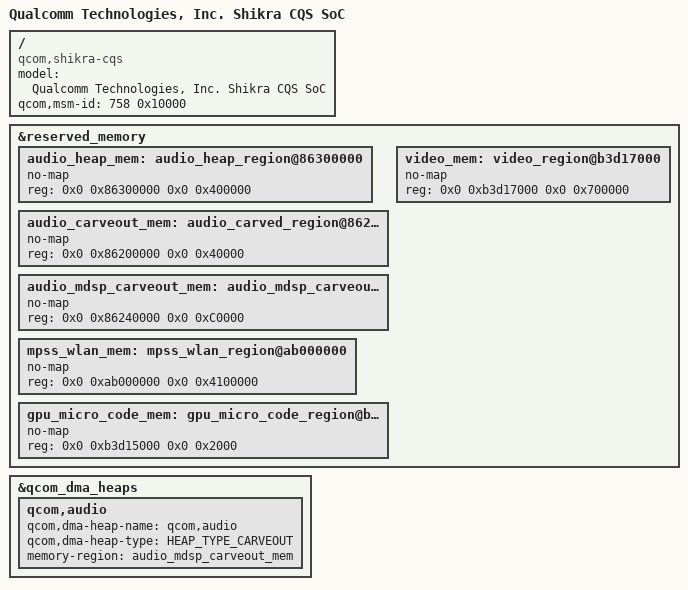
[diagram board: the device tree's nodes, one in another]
// SPDX-License-Identifier: BSD-3-Clause
/*
 * Copyright (c) Qualcomm Technologies, Inc. and/or its subsidiaries.
 */

#include "shikra.dtsi"
#include "shikra-pmic-overlay-pm4125.dtsi"

/ {
	model = "Qualcomm Technologies, Inc. Shikra CQS SoC";
	compatible = "qcom,shikra-cqs";
	qcom,msm-id = <758 0x10000>;
};

&reserved_memory {
	#address-cells = <2>;
	#size-cells = <2>;
	ranges;


	/delete-node/ display_config_region@84c00000;

	/delete-node/ pvm_fw_region@86300000;
	audio_heap_mem: audio_heap_region@86300000 {
		no-map;
		reg = <0x0 0x86300000 0x0 0x400000>;
	};

	/delete-node/ audio_carved_region@86200000;
	audio_carveout_mem: audio_carved_region@86200000 {
		no-map;
		reg = <0x0 0x86200000 0x0 0x40000>;
	};

	audio_mdsp_carveout_mem: audio_mdsp_carveout_region@86240000 {
		no-map;
		reg = <0x0 0x86240000 0x0 0xC0000>;
	};

	/* UEFI region at 0x9F800000 is reclaimed by Linux */

	/delete-node/ mpss_wlan_region@ab000000;
	mpss_wlan_mem: mpss_wlan_region@ab000000 {
		no-map;
		reg = <0x0 0xab000000 0x0 0x4100000>;
	};

	/delete-node/ ipa_fw_region@b3d00000;
	/delete-node/ ipa_gsi_region@b3d10000;

	/delete-node/ gpu_micro_code_region@b3d00000;
	gpu_micro_code_mem: gpu_micro_code_region@b3d15000 {
		no-map;
		reg = <0x0 0xb3d15000 0x0 0x2000>;
	};

	/delete-node/ video_region@b3d02000;
	video_mem: video_region@b3d17000 {
		no-map;
		reg = <0x0 0xb3d17000 0x0 0x700000>;
	};
};

&qcom_dma_heaps {
	qcom,audio {
		qcom,dma-heap-name = "qcom,audio";
		qcom,dma-heap-type = <HEAP_TYPE_CARVEOUT>;
		memory-region = <&audio_mdsp_carveout_mem>;
	};
};
